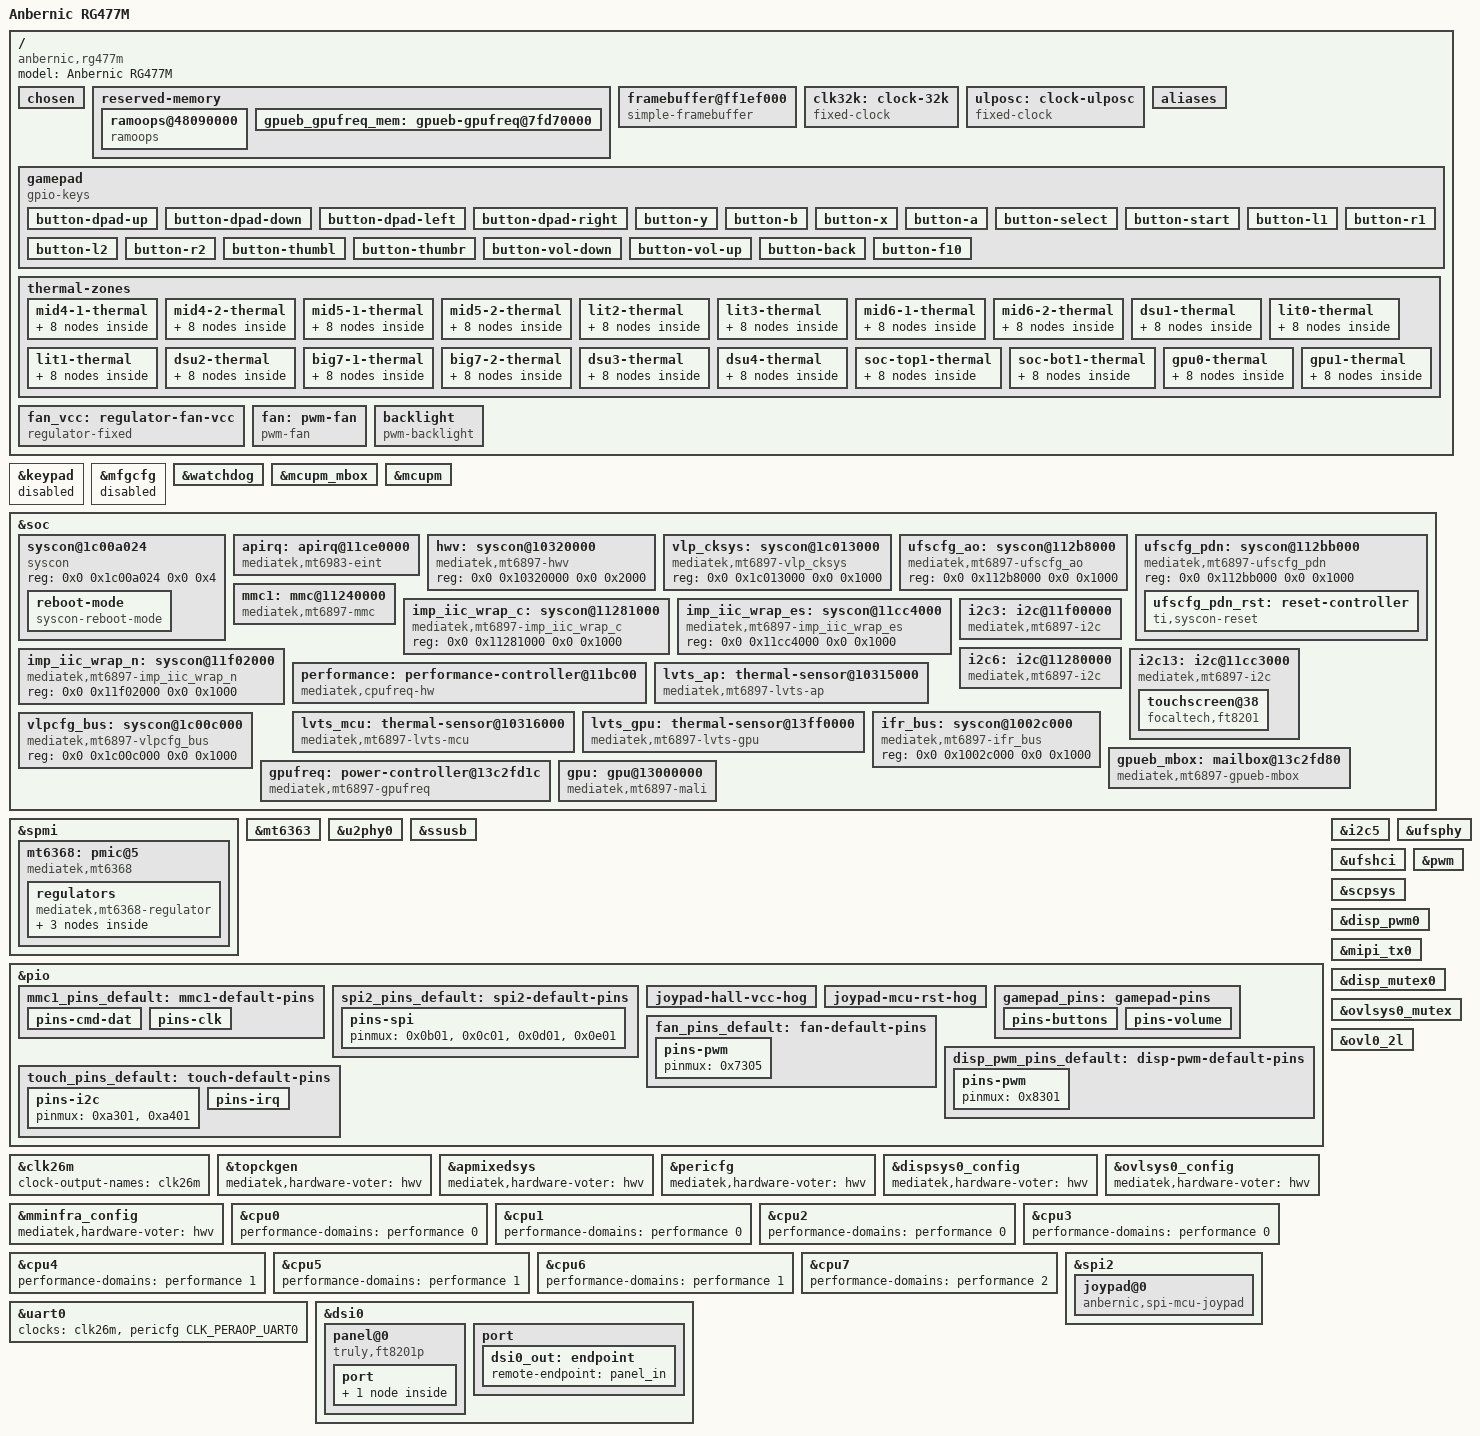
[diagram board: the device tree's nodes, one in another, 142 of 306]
// SPDX-License-Identifier: GPL-2.0 OR BSD-3-Clause
/*
 * Anbernic RG477M (MediaTek MT6897 / Dimensity 8300) - first-boot board file.
 *
 * This tree is embedded in the kernel (CONFIG_ARM64_EMBEDDED_DTB). The
 * bootloader is given the stock vendor tree; early boot code takes memory size,
 * the initramfs location and every /reserved-memory region from that tree and
 * then switches to this one. So there is deliberately no /memory node and no
 * copy of the bootloader's reserved regions here.
 *
 * Stage 1 goal: reach an initramfs with the kernel log visible on the panel
 * (bootloader framebuffer) and preserved in ramoops.
 *
 * Stage 2 adds the watchdog, the PMIC bus and USB device mode. There is no
 * clock driver yet: nodes use 26 MHz placeholders and rely on the state the
 * bootloader left behind (clk_ignore_unused).
 */

/dts-v1/;
#include "mt6897.dtsi"
#include <dt-bindings/clock/mt6897-clk.h>

/ {
	model = "Anbernic RG477M";
	compatible = "anbernic,rg477m", "mediatek,mt6897";

	/*
	 * The bootloader leaves the hardware watchdog armed (about 28 s). The
	 * driver takes it over and the core keeps it fed for
	 * watchdog.open_timeout seconds; after that userspace must hold
	 * /dev/watchdog open, so a boot that never reaches a working init is
	 * still reset and falls back to the other slot.
	 */
	chosen {
		bootargs = "bootconfig console=ttyS0,921600n8 console=tty0 ignore_loglevel printk.devkmsg=on clk_ignore_unused pd_ignore_unused panic=5 watchdog.open_timeout=45";
	};

	reserved-memory {
		#address-cells = <2>;
		#size-cells = <2>;
		ranges;

		/*
		 * Same region and zone layout as the vendor kernel (which gets it from
		 * ramoops.* parameters with 4 KiB record and ftrace zones), so the log
		 * written here is readable as /sys/fs/pstore/console-ramoops-0 after the
		 * device has fallen back to Android. The bootloader marks this region
		 * no-map; that is carried over by the early import.
		 */
		ramoops@48090000 {
			compatible = "ramoops";
			reg = <0x0 0x48090000 0x0 0xe0000>;
			record-size = <0x1000>;
			console-size = <0x40000>;
			ftrace-size = <0x1000>;
			pmsg-size = <0x80000>;
		};

		/*
		 * MEM_ID_GPUFREQ: the first 0x4000 bytes of the bootloader's
		 * me_GPUEB_SHARED (0x7fd70000 + 0x180000 on this board; the
		 * tablet's 0x7fe70000 in mt6897.dtsi is not ours). The GPUEB
		 * writes struct gpufreq_shared_status here after
		 * CMD_INIT_SHARED_MEM. The early import already marks the whole
		 * region no-map; this node only lets the driver find it.
		 */
		gpueb_gpufreq_mem: gpueb-gpufreq@7fd70000 {
			reg = <0x0 0x7fd70000 0x0 0x4000>;
			no-map;
		};
	};

	/*
	 * Scan-out buffer left running by the bootloader (its mblock "framebuffer":
	 * 0xff1ef000, 0xe10000 bytes = 3 x 1280x960x4). The region itself is taken
	 * from the bootloader tree and kept out of the linear map by the early
	 * import. The address was read on a 12 GB unit; if another RAM size places
	 * it elsewhere, read it from the bootloader tree instead of fixing it here.
	 */
	framebuffer@ff1ef000 {
		compatible = "simple-framebuffer";
		reg = <0x0 0xff1ef000 0x0 0xe10000>;
		width = <1280>;
		height = <960>;
		stride = <5120>;
		format = "a8r8g8b8";
		/*
		 * The bootloader's pipeline runs from mmpll (disp0, ovl0 and
		 * mminfra all select mmpll_d4). Hold those here: UFS borrows
		 * mmpll_d6 during bring-up, and when it lets go the PLL would
		 * otherwise be switched off under the panel (seen as the
		 * console going black at SCSI attach).
		 */
		clocks = <&topckgen CLK_TOP_DISP0_SEL>,
			 <&topckgen CLK_TOP_OVL0_SEL>,
			 <&topckgen CLK_TOP_MMINFRA_SEL>,
			 <&pericfg CLK_PERAOP_DISP_PWM0>;
	};
};

/*
 * The SoC file's gpu and gpueb nodes belong to the vendor-derived GPUEB path
 * of the tablet (CONFIG_MTK_GPUEB, wrong shared-memory address for this board,
 * mfgcfg clocks). Drop them so nothing on this board can match that driver or
 * the panthor hooks keyed on a "mediatek,gpueb" node; the GPU is described
 * again below for the mainline mailbox + mt6897-gpufreq power domain.
 */
/delete-node/ &gpu;
/delete-node/ &gpueb;

/* Nothing below is needed to reach an initramfs; enable one at a time later. */

&keypad {
	status = "disabled";
};

&mfgcfg {
	status = "disabled";
};



&watchdog {
	status = "okay";
};

/*
 * MCUPM mailbox and bring-up client (CPU idle states experiment): the client
 * sends the vendor's platform IPI and timesync at probe, each switchable with
 * mtk_mcupm_mt6897.ping= / .timesync=, and logs the ATF/MCUPM state words.
 */
&mcupm_mbox {
	status = "okay";
};

&mcupm {
	status = "okay";
};

&soc {
	/*
	 * The bootloader reads its boot mode from the low nibble of the
	 * watchdog's non-reset register 2 (0x1c00a024), same as the vendor
	 * tree's reboot-mode node. "reboot bootloader" lands in fastboot, where
	 * the host can switch the active slot back without waiting for the
	 * retry counter to run out. Kept as its own syscon so the watchdog
	 * driver can own the main register block.
	 */
	syscon@1c00a024 {
		compatible = "syscon", "simple-mfd";
		reg = <0x0 0x1c00a024 0x0 0x4>;

		reboot-mode {
			compatible = "syscon-reboot-mode";
			offset = <0x0>;
			mask = <0xf>;
			mode-charger = <0x1>;
			mode-recovery = <0x2>;
			mode-bootloader = <0x3>;
		};
	};
};

/*
 * PMIC bus. The PMIC interrupt line is EINT 248 of the pin controller (the
 * dtsi already says so). Only VUSB is described, with the vendor tree's limits
 * and always-on, so nothing changes any rail's state or voltage. The power
 * and volume-down ("home") keys on the MT6363 are polled by the keys driver.
 */
&spmi {
	status = "okay";

	mt6368: pmic@5 {
		compatible = "mediatek,mt6368";
		reg = <5 0>;
		interrupts = <5>;
		interrupt-controller;
		#interrupt-cells = <2>;

		regulators {
			compatible = "mediatek,mt6368-regulator";

			mt6368_vusb: VUSB {
				regulator-compatible = "VUSB";
				regulator-name = "mt6368_vusb";
				regulator-min-microvolt = <1200000>;
				regulator-max-microvolt = <3500000>;
				regulator-enable-ramp-delay = <680>;
				regulator-always-on;
			};

			/*
			 * SD card supplies. The stock tree lists the LDOs' full
			 * 1.2-3.5 V range and limits the card to 3.0 V with a
			 * vendor-only "ocr-voltage" property; without that the
			 * MMC core picked 3.5 V for both rails. Limit them here:
			 * 3.0 V card supply, 1.8-3.0 V signalling.
			 */
			mt6368_vmch_eint_high: VMCH_EINT_HIGH {
				regulator-compatible = "VMCH_EINT_HIGH";
				regulator-name = "mt6368_vmch_eint_high";
				regulator-min-microvolt = <2800000>;
				regulator-max-microvolt = <3000000>;
				regulator-enable-ramp-delay = <680>;
			};

			mt6368_vmc: VMC {
				regulator-compatible = "VMC";
				regulator-name = "mt6368_vmc";
				regulator-min-microvolt = <1800000>;
				regulator-max-microvolt = <3000000>;
				regulator-enable-ramp-delay = <680>;
			};
		};
	};
};

&mt6363 {
	interrupts = <4>;
	interrupt-controller;
	#interrupt-cells = <2>;
};

/* USB device mode only; no Type-C role detection yet. */
&u2phy0 {
	status = "okay";
};

&ssusb {
	dr_mode = "peripheral";
	maximum-speed = "high-speed";
	mediatek,force-vbus;
	phys = <&u2port0 PHY_TYPE_USB2>;
	vusb33-supply = <&mt6368_vusb>;
	status = "okay";
};

/*
 * Pin controller. Register block names and order, and the EINT block with its
 * number -> (instance, index, debounce) table, are the stock tree's.
 */
&soc {
	apirq: apirq@11ce0000 {
		compatible = "mediatek,mt6983-eint";
		reg = <0x0 0x11ce0000 0x0 0x1000>,
		      <0x0 0x11de0000 0x0 0x1000>,
		      <0x0 0x11e90000 0x0 0x1000>,
		      <0x0 0x11fe0000 0x0 0x1000>,
		      <0x0 0x1c01e000 0x0 0x1000>;
		reg-names = "eint-e", "eint-s", "eint-w", "eint-n", "eint-c";
		interrupts = <GIC_SPI 309 IRQ_TYPE_LEVEL_HIGH 0>;
		mediatek,instance-num = <5>;
		mediatek,total-pin-number = <250>;
		mediatek,pins = <
			0x00 0x03 0x00 0x01 0x01 0x03 0x01 0x01 0x02 0x03 0x02 0x01 0x03 0x03 0x03 0x01
			0x04 0x00 0x00 0x01 0x05 0x00 0x01 0x01 0x06 0x00 0x02 0x01 0x07 0x03 0x04 0x01
			0x08 0x02 0x00 0x01 0x09 0x03 0x05 0x01 0x0a 0x03 0x06 0x01 0x0b 0x03 0x07 0x01
			0x0c 0x03 0x08 0x01 0x0d 0x03 0x09 0x01 0x0e 0x03 0x0a 0x01 0x0f 0x01 0x00 0x01
			0x10 0x01 0x01 0x01 0x11 0x01 0x02 0x01 0x12 0x01 0x03 0x01 0x13 0x01 0x04 0x01
			0x14 0x01 0x05 0x01 0x15 0x01 0x06 0x01 0x16 0x01 0x07 0x01 0x17 0x01 0x08 0x01
			0x18 0x01 0x09 0x01 0x19 0x01 0x0a 0x01 0x1a 0x01 0x0b 0x01 0x1b 0x01 0x0c 0x01
			0x1c 0x01 0x0d 0x01 0x1d 0x01 0x0e 0x01 0x1e 0x01 0x0f 0x01 0x1f 0x02 0x01 0x01
			0x20 0x02 0x02 0x01 0x21 0x02 0x03 0x01 0x22 0x02 0x04 0x01 0x23 0x02 0x05 0x00
			0x24 0x01 0x10 0x00 0x25 0x01 0x11 0x00 0x26 0x01 0x12 0x00 0x27 0x01 0x13 0x00
			0x28 0x03 0x0b 0x00 0x29 0x03 0x0c 0x00 0x2a 0x03 0x0d 0x00 0x2b 0x03 0x0e 0x00
			0x2c 0x00 0x03 0x00 0x2d 0x00 0x04 0x00 0x2e 0x00 0x05 0x00 0x2f 0x00 0x06 0x00
			0x30 0x00 0x07 0x00 0x31 0x00 0x08 0x00 0x32 0x02 0x06 0x00 0x33 0x02 0x07 0x00
			0x34 0x02 0x08 0x00 0x35 0x02 0x09 0x00 0x36 0x03 0x0f 0x00 0x37 0x03 0x10 0x00
			0x38 0x03 0x11 0x00 0x39 0x03 0x12 0x00 0x3a 0x03 0x13 0x00 0x3b 0x03 0x14 0x00
			0x3c 0x03 0x15 0x00 0x3d 0x03 0x16 0x00 0x3e 0x00 0x09 0x00 0x3f 0x00 0x0a 0x00
			0x40 0x00 0x0b 0x00 0x41 0x00 0x0c 0x00 0x42 0x02 0x0a 0x00 0x43 0x02 0x0b 0x00
			0x44 0x02 0x0c 0x00 0x45 0x02 0x0d 0x00 0x46 0x02 0x0e 0x00 0x47 0x02 0x0f 0x00
			0x48 0x02 0x10 0x00 0x49 0x02 0x11 0x00 0x4a 0x02 0x12 0x00 0x4b 0x02 0x13 0x00
			0x4c 0x02 0x14 0x00 0x4d 0x02 0x15 0x00 0x4e 0x00 0x0d 0x00 0x4f 0x00 0x0e 0x00
			0x50 0x00 0x0f 0x00 0x51 0x00 0x10 0x00 0x52 0x00 0x11 0x00 0x53 0x00 0x12 0x00
			0x54 0x01 0x14 0x00 0x55 0x01 0x15 0x00 0x56 0x01 0x16 0x00 0x57 0x01 0x17 0x00
			0x58 0x01 0x18 0x00 0x59 0x01 0x19 0x00 0x5a 0x01 0x1a 0x00 0x5b 0x01 0x1b 0x00
			0x5c 0x01 0x1c 0x00 0x5d 0x01 0x1d 0x00 0x5e 0x01 0x1e 0x00 0x5f 0x01 0x1f 0x00
			0x60 0x01 0x20 0x00 0x61 0x01 0x21 0x00 0x62 0x01 0x22 0x00 0x63 0x01 0x23 0x00
			0x64 0x01 0x24 0x00 0x65 0x01 0x25 0x00 0x66 0x01 0x26 0x00 0x67 0x01 0x27 0x00
			0x68 0x01 0x28 0x00 0x69 0x01 0x29 0x00 0x6a 0x01 0x2a 0x00 0x6b 0x01 0x2b 0x00
			0x6c 0x01 0x2c 0x00 0x6d 0x01 0x2d 0x00 0x6e 0x01 0x2e 0x00 0x6f 0x01 0x2f 0x00
			0x70 0x01 0x30 0x00 0x71 0x01 0x31 0x00 0x72 0x01 0x32 0x00 0x73 0x00 0x13 0x00
			0x74 0x00 0x14 0x00 0x75 0x00 0x15 0x00 0x76 0x01 0x33 0x00 0x77 0x00 0x16 0x00
			0x78 0x00 0x17 0x00 0x79 0x00 0x18 0x00 0x7a 0x01 0x34 0x00 0xe8 0x04 0x00 0x00
			0xe9 0x04 0x01 0x00 0xea 0x04 0x02 0x00 0xeb 0x04 0x03 0x00 0xec 0x04 0x04 0x00
			0xed 0x04 0x05 0x00 0xee 0x04 0x06 0x00 0xef 0x04 0x07 0x00 0xf0 0x04 0x08 0x00
			0xf1 0x04 0x09 0x00 0xf2 0x04 0x0a 0x00 0xf3 0x04 0x0b 0x00 0xf4 0x04 0x0c 0x00
			0xf5 0x04 0x0d 0x00 0xf6 0x04 0x0e 0x00 0xf7 0x04 0x0f 0x00 0xf8 0x04 0x10 0x00
			0xf9 0x04 0x11 0x00>;
	};
};

&pio {
	reg-names = "gpio", "iocfg_rt", "iocfg_rm", "iocfg_bl", "iocfg_bm",
		    "iocfg_br", "iocfg_lb", "iocfg_lt", "iocfg_tm", "iocfg_tl";
	gpio-ranges = <&pio 0 0 250>;
	mediatek,eint = <&apirq>;
};

/*
 * Clock controllers. Registration only for now: no consumer references them
 * yet and the kernel runs with clk_ignore_unused, so the tree mirrors the state
 * the bootloader left. The CPU, GPU and SCP PLL blocks are left out until
 * something needs them. Do not add assigned-clocks to these nodes.
 */
&clk26m {
	clock-output-names = "clk26m";
};

/ {
	clk32k: clock-32k {
		compatible = "fixed-clock";
		#clock-cells = <0>;
		clock-frequency = <32000>;
		clock-output-names = "clk32k";
	};

	ulposc: clock-ulposc {
		compatible = "fixed-clock";
		#clock-cells = <0>;
		clock-frequency = <588000000>;
		clock-output-names = "ulposc";
	};
};

&soc {
	hwv: syscon@10320000 {
		compatible = "mediatek,mt6897-hwv", "syscon";
		reg = <0x0 0x10320000 0x0 0x2000>;
	};

	vlp_cksys: syscon@1c013000 {
		compatible = "mediatek,mt6897-vlp_cksys", "syscon";
		reg = <0x0 0x1c013000 0x0 0x1000>;
		#clock-cells = <1>;
	};

	ufscfg_ao: syscon@112b8000 {
		compatible = "mediatek,mt6897-ufscfg_ao", "syscon";
		reg = <0x0 0x112b8000 0x0 0x1000>;
		#clock-cells = <1>;
	};

	ufscfg_pdn: syscon@112bb000 {
		compatible = "mediatek,mt6897-ufscfg_pdn", "syscon", "simple-mfd";
		reg = <0x0 0x112bb000 0x0 0x1000>;
		#clock-cells = <1>;

		/* UniPro, crypto and host controller resets, as in the stock tree. */
		ufscfg_pdn_rst: reset-controller {
			compatible = "ti,syscon-reset";
			#reset-cells = <1>;
			ti,reset-bits = <0x48 0 0x4c 0 0 0 0x1c>,
					<0x48 1 0x4c 1 0 0 0x1c>,
					<0x48 2 0x4c 2 0 0 0x1c>;
		};
	};
};

&topckgen {
	mediatek,hardware-voter = <&hwv>;
};

&apmixedsys {
	mediatek,hardware-voter = <&hwv>;
};

&pericfg {
	mediatek,hardware-voter = <&hwv>;
};

/*
 * Display clock gates used by the bootloader's pipeline (DSI0 path through
 * dispsys0/ovlsys0, SMI/GCE on mminfra). Registration is read-free and
 * write-free; the gates are only touched once a consumer enables them.
 * The three power domains are registered on and always-on by scpsys.
 */
&dispsys0_config {
	mediatek,hardware-voter = <&hwv>;
	status = "okay";
};

&ovlsys0_config {
	mediatek,hardware-voter = <&hwv>;
	status = "okay";
};

&mminfra_config {
	mediatek,hardware-voter = <&hwv>;
	status = "okay";
};

/*
 * microSD slot (MSDC1). Pins, supplies and card detect are the stock tree's;
 * its raw drive-strength index 3 is 8 mA.
 */
&pio {
	mmc1_pins_default: mmc1-default-pins {
		pins-cmd-dat {
			pinmux = <0x4a01>, <0x4b01>, <0x4c01>, <0x4d01>, <0x4901>;
			input-enable;
			drive-strength = <8>;
			bias-pull-up = <101>;
		};

		pins-clk {
			pinmux = <0x4801>;
			drive-strength = <8>;
			bias-pull-down = <102>;
		};
	};
};

&soc {
	mmc1: mmc@11240000 {
		compatible = "mediatek,mt6897-mmc";
		reg = <0x0 0x11240000 0x0 0x1000>,
		      <0x0 0x11e00000 0x0 0x1000>;
		interrupts = <GIC_SPI 166 IRQ_TYPE_LEVEL_HIGH 0>;
		clocks = <&topckgen CLK_TOP_MSDC30_1_SEL>,
			 <&pericfg CLK_PERAOP_MSDC1_HCLK>,
			 <&pericfg CLK_PERAOP_MSDC1>,
			 <&pericfg CLK_PERAOP_MSDC1_FCLK>;
		/*
		 * PERAOP_MSDC1 is deliberately not "source_cg": the driver
		 * gates that clock while it programs the divider, and on this
		 * SoC the same gate also clocks the register interface, so the
		 * divider write was lost (CKDIV read back 0 and the card was
		 * clocked far too fast). The vendor driver never gates it here
		 * (need_gate_cg = false).
		 */
		clock-names = "source", "hclk", "pclk_cg", "axi_cg";
		pinctrl-names = "default", "state_uhs";
		pinctrl-0 = <&mmc1_pins_default>;
		pinctrl-1 = <&mmc1_pins_default>;
		bus-width = <4>;
		max-frequency = <200000000>;
		cap-sd-highspeed;
		sd-uhs-sdr12;
		sd-uhs-sdr25;
		sd-uhs-sdr50;
		sd-uhs-sdr104;
		cd-gpios = <&pio 33 GPIO_ACTIVE_LOW>;
		vmmc-supply = <&mt6368_vmch_eint_high>;
		vqmmc-supply = <&mt6368_vmc>;
		no-mmc;
		no-sdio;
		status = "okay";
	};
};

/*
 * I2C. Only the buses with board devices on them: i2c3 (RT9465 charger),
 * i2c5 (MT6375 charger/Type-C, RT6160, RT5133), i2c6 (panel gate IC, PS5170
 * redriver, speaker amp, flash LED driver), i2c13 (touchscreen). No client
 * devices are described yet; the buses are up for probing only. Pins are left
 * as the bootloader muxed them, as in the stock tree.
 */
&soc {
	imp_iic_wrap_c: syscon@11281000 {
		compatible = "mediatek,mt6897-imp_iic_wrap_c", "syscon";
		reg = <0x0 0x11281000 0x0 0x1000>;
		#clock-cells = <1>;
	};

	imp_iic_wrap_es: syscon@11cc4000 {
		compatible = "mediatek,mt6897-imp_iic_wrap_es", "syscon";
		reg = <0x0 0x11cc4000 0x0 0x1000>;
		#clock-cells = <1>;
	};

	imp_iic_wrap_n: syscon@11f02000 {
		compatible = "mediatek,mt6897-imp_iic_wrap_n", "syscon";
		reg = <0x0 0x11f02000 0x0 0x1000>;
		#clock-cells = <1>;
	};

	i2c3: i2c@11f00000 {
		compatible = "mediatek,mt6897-i2c";
		reg = <0x0 0x11f00000 0x0 0x1000>,
		      <0x0 0x11300400 0x0 0x80>;
		interrupts = <GIC_SPI 189 IRQ_TYPE_LEVEL_HIGH 0>;
		clocks = <&imp_iic_wrap_n CLK_IMPN_AP_CLOCK_I2C3>,
			 <&pericfg CLK_PERAOP_DMA_BCLK>;
		clock-names = "main", "dma";
		clock-div = <1>;
		clock-frequency = <100000>;
		#address-cells = <1>;
		#size-cells = <0>;
	};

	i2c6: i2c@11280000 {
		compatible = "mediatek,mt6897-i2c";
		reg = <0x0 0x11280000 0x0 0x1000>,
		      <0x0 0x11300600 0x0 0x80>;
		interrupts = <GIC_SPI 192 IRQ_TYPE_LEVEL_HIGH 0>;
		clocks = <&imp_iic_wrap_c CLK_IMPC_AP_CLOCK>,
			 <&pericfg CLK_PERAOP_DMA_BCLK>;
		clock-names = "main", "dma";
		clock-div = <1>;
		clock-frequency = <100000>;
		#address-cells = <1>;
		#size-cells = <0>;
	};

	i2c13: i2c@11cc3000 {
		compatible = "mediatek,mt6897-i2c";
		reg = <0x0 0x11cc3000 0x0 0x1000>,
		      <0x0 0x11300b00 0x0 0x80>;
		interrupts = <GIC_SPI 199 IRQ_TYPE_LEVEL_HIGH 0>;
		clocks = <&imp_iic_wrap_es CLK_IMPES_AP_CLOCK_I2C13>,
			 <&pericfg CLK_PERAOP_DMA_BCLK>;
		clock-names = "main", "dma";
		clock-div = <1>;
		clock-frequency = <100000>;
		#address-cells = <1>;
		#size-cells = <0>;
	};
};

&i2c5 {
	clocks = <&imp_iic_wrap_n CLK_IMPN_AP_CLOCK_I2C5>,
		 <&pericfg CLK_PERAOP_DMA_BCLK>;
	clock-frequency = <100000>;
	status = "okay";
};

/ {
	aliases {
		i2c3 = &i2c3;
		i2c5 = &i2c5;
		i2c6 = &i2c6;
		i2c13 = &i2c13;
		mmc1 = &mmc1;
	};
};

/* USB on its real clocks instead of whatever the bootloader left running. */
&ssusb {
	clocks = <&topckgen CLK_TOP_USB_TOP>,
		 <&topckgen CLK_TOP_USB_XHCI>,
		 <&pericfg CLK_PERAOP_SSUSB0_FRMCNT>;
	clock-names = "sys_ck", "xhci_ck", "frmcnt_ck";
};

/*
 * CPU frequency scaling through the MCU power manager's shared tables (same
 * node as the stock tree). There is no thermal driver or fan control yet, so
 * userspace should cap scaling_max_freq until there is.
 */
&soc {
	performance: performance-controller@11bc00 {
		compatible = "mediatek,cpufreq-hw";
		reg = <0x0 0x0011bc10 0x0 0x120>,
		      <0x0 0x0011bd30 0x0 0x120>,
		      <0x0 0x0011be50 0x0 0x120>;
		reg-names = "performance-domain0", "performance-domain1",
			    "performance-domain2";
		#performance-domain-cells = <1>;
	};
};

&cpu0 { performance-domains = <&performance 0>; };
&cpu1 { performance-domains = <&performance 0>; };
&cpu2 { performance-domains = <&performance 0>; };
&cpu3 { performance-domains = <&performance 0>; };
&cpu4 { performance-domains = <&performance 1>; };
&cpu5 { performance-domains = <&performance 1>; };
&cpu6 { performance-domains = <&performance 1>; };
&cpu7 { performance-domains = <&performance 2>; };

/*
 * Analog sticks: an MCU on SPI2 (GPIO11-14), same protocol as other recent
 * Anbernic handhelds. The stock tree drives five GPIOs high for it: MCU supply
 * (27), MCU reset (28, high = running), hall sensor supply (36), and the stick
 * LED supply and enable (65, 30). The LED pair is left alone for now. Axis
 * limits are the ROCKNIX defaults for this MCU, not yet calibrated here.
 */
&pio {
	spi2_pins_default: spi2-default-pins {
		pins-spi {
			pinmux = <0x0b01>, <0x0c01>, <0x0d01>, <0x0e01>;
		};
	};

	joypad-hall-vcc-hog {
		gpio-hog;
		gpios = <36 GPIO_ACTIVE_HIGH>;
		output-high;
		line-name = "joypad-hall-vcc";
	};

	joypad-mcu-rst-hog {
		gpio-hog;
		gpios = <28 GPIO_ACTIVE_HIGH>;
		output-high;
		line-name = "joypad-mcu-rst";
	};
};

&spi2 {
	clocks = <&topckgen CLK_TOP_MAINPLL_D6_D2>,
		 <&topckgen CLK_TOP_SPI2_SEL>,
		 <&pericfg CLK_PERAOP_SPI2_BCLK>;
	clock-names = "parent-clk", "sel-clk", "spi-clk";
	pinctrl-names = "default";
	pinctrl-0 = <&spi2_pins_default>;
	status = "okay";

	joypad@0 {
		compatible = "anbernic,spi-mcu-joypad";
		reg = <0>;
		spi-max-frequency = <1400000>;
		/* Give the MCU time between chip select and the first clock. */
		spi-cs-setup-delay-ns = <100000>;
		enable-gpios = <&pio 27 GPIO_ACTIVE_HIGH>;
		poll-interval-ms = <5>;
		swap-sticks;
		abs-x-min = <2500>;
		abs-x-max = <25000>;
		abs-y-min = <2500>;
		abs-y-max = <25000>;
		abs-rx-min = <2500>;
		abs-rx-max = <25000>;
		abs-ry-min = <2500>;
		abs-ry-max = <25000>;
		deadzone-left = <3000>;
		deadzone-right = <3000>;
		deadzone-triggers = <32000>;
	};
};

/*
 * Buttons: twenty active-low GPIO switches, the list and key codes of the
 * stock tree's "singleadc-joypad" node (which has no analog inputs on this
 * board). L2/R2 are plain switches, not analog triggers.
 */
#include <dt-bindings/input/input.h>

&pio {
	gamepad_pins: gamepad-pins {
		pins-buttons {
			pinmux = <0x0100>, <0x0300>, <0x0600>, <0x0800>, <0x0a00>,
				 <0x0f00>, <0x1000>, <0x1100>, <0x1200>, <0x1300>,
				 <0x1400>, <0x1500>, <0x1600>, <0x1700>, <0x1800>,
				 <0x1900>, <0x1a00>, <0x3d00>;
			input-enable;
			bias-pull-up;
		};

		/* GPIO31/32 have R1R0 pull resistors; 101 is the stock setting. */
		pins-volume {
			pinmux = <0x1f00>, <0x2000>;
			input-enable;
			bias-pull-up = <101>;
		};
	};
};

/ {
	gamepad {
		compatible = "gpio-keys";
		label = "RG477M Gamepad";
		pinctrl-names = "default";
		pinctrl-0 = <&gamepad_pins>;

		button-dpad-up {
			label = "DPAD-UP";
			gpios = <&pio 19 GPIO_ACTIVE_LOW>;
			linux,input-type = <EV_ABS>;
			linux,code = <ABS_HAT0Y>;
			linux,input-value = <(-1)>;
			debounce-interval = <2>;
		};

		button-dpad-down {
			label = "DPAD-DOWN";
			gpios = <&pio 22 GPIO_ACTIVE_LOW>;
			linux,input-type = <EV_ABS>;
			linux,code = <ABS_HAT0Y>;
			linux,input-value = <1>;
			debounce-interval = <2>;
		};

		button-dpad-left {
			label = "DPAD-LEFT";
			gpios = <&pio 20 GPIO_ACTIVE_LOW>;
			linux,input-type = <EV_ABS>;
			linux,code = <ABS_HAT0X>;
			linux,input-value = <(-1)>;
			debounce-interval = <2>;
		};

		button-dpad-right {
			label = "DPAD-RIGHT";
			gpios = <&pio 21 GPIO_ACTIVE_LOW>;
			linux,input-type = <EV_ABS>;
			linux,code = <ABS_HAT0X>;
			linux,input-value = <1>;
			debounce-interval = <2>;
		};

		button-y { label = "BTN-Y"; gpios = <&pio 24 GPIO_ACTIVE_LOW>; linux,code = <0x134>; debounce-interval = <2>; };
		button-b { label = "BTN-B"; gpios = <&pio 26 GPIO_ACTIVE_LOW>; linux,code = <0x131>; debounce-interval = <2>; };
		button-x { label = "BTN-X"; gpios = <&pio 23 GPIO_ACTIVE_LOW>; linux,code = <0x133>; debounce-interval = <2>; };
		button-a { label = "BTN-A"; gpios = <&pio 25 GPIO_ACTIVE_LOW>; linux,code = <0x130>; debounce-interval = <2>; };
		button-select { label = "SELECT"; gpios = <&pio 8 GPIO_ACTIVE_LOW>; linux,code = <BTN_SELECT>; debounce-interval = <2>; };
		button-start { label = "START"; gpios = <&pio 10 GPIO_ACTIVE_LOW>; linux,code = <BTN_START>; debounce-interval = <2>; };
		button-l1 { label = "L1"; gpios = <&pio 16 GPIO_ACTIVE_LOW>; linux,code = <BTN_TL>; debounce-interval = <2>; };
		button-r1 { label = "R1"; gpios = <&pio 15 GPIO_ACTIVE_LOW>; linux,code = <BTN_TR>; debounce-interval = <2>; };
		button-l2 { label = "L2"; gpios = <&pio 61 GPIO_ACTIVE_LOW>; linux,code = <BTN_TL2>; debounce-interval = <5>; };
		button-r2 { label = "R2"; gpios = <&pio 1 GPIO_ACTIVE_LOW>; linux,code = <BTN_TR2>; debounce-interval = <5>; };
		button-thumbl { label = "L3"; gpios = <&pio 18 GPIO_ACTIVE_LOW>; linux,code = <BTN_THUMBL>; debounce-interval = <2>; };
		button-thumbr { label = "R3"; gpios = <&pio 6 GPIO_ACTIVE_LOW>; linux,code = <BTN_THUMBR>; debounce-interval = <2>; };
		button-vol-down { label = "VOL-DOWN"; gpios = <&pio 31 GPIO_ACTIVE_LOW>; linux,code = <KEY_VOLUMEDOWN>; debounce-interval = <2>; };
		button-vol-up { label = "VOL-UP"; gpios = <&pio 32 GPIO_ACTIVE_LOW>; linux,code = <KEY_VOLUMEUP>; debounce-interval = <2>; };
		button-back { label = "BACK"; gpios = <&pio 17 GPIO_ACTIVE_LOW>; linux,code = <KEY_BACK>; debounce-interval = <2>; };
		button-f10 { label = "F10"; gpios = <&pio 3 GPIO_ACTIVE_LOW>; linux,code = <KEY_F10>; debounce-interval = <2>; };
	};
};

/*
 * UFS: clocks and host resets as in the stock tree. No supplies yet, so the
 * kernel cannot power-cycle the device and the rails stay as the bootloader
 * left them; that waits for suspend/power-off work, where a wrong voltage
 * limit would matter. Single interrupt, MCQ off.
 * This holds the Android installation: test userspace marks every disk
 * read-only as it appears and nothing here may mount it read-write.
 */
&ufsphy {
	status = "okay";
};

&ufshci {
	clocks = <&topckgen CLK_TOP_U_SEL>,
		 <&topckgen CLK_TOP_MAINPLL_D4_D2>,
		 <&topckgen CLK_TOP_MMPLL_D6>,
		 <&topckgen CLK_TOP_AES_UFSFDE_SEL>,
		 <&topckgen CLK_TOP_UNIVPLL_D6>,
		 <&topckgen CLK_TOP_MAINPLL_D4>,
		 <&ufscfg_ao CLK_UFSCFG_AO_UNIPRO_TX_SYMBOLCLK>,
		 <&ufscfg_ao CLK_UFSCFG_AO_UNIPRO_RX_SYMBOLCLK0>,
		 <&ufscfg_ao CLK_UFSCFG_AO_UNIPRO_RX_SYMBOLCLK1>,
		 <&ufscfg_ao CLK_UFSCFG_AO_UNIPRO_SYSCLK>,
		 <&ufscfg_pdn CLK_UFSCFG_UFSHCI_UFS>,
		 <&ufscfg_pdn CLK_UFSCFG_UFSHCI_AES>;
	clock-names = "ufs_sel", "ufs_sel_min_src", "ufs_sel_max_src",
		      "ufs_fde", "ufs_fde_min_src", "ufs_fde_max_src",
		      "unipro_tx_sym", "unipro_rx_sym0", "unipro_rx_sym1",
		      "unipro_sysclk", "ufshci_ufs", "ufshci_aes";
	freq-table-hz = <273000000 458333313>, <0 0>, <0 0>, <0 0>, <0 0>,
			<0 0>, <0 0>, <0 0>, <0 0>, <0 0>, <0 0>, <0 0>;
	mediatek,ufs-pmc-via-fastauto;
	mediatek,ufs-tx-skew-fix;
	mediatek,ufs-disable-mcq;
	resets = <&ufscfg_pdn_rst 0>, <&ufscfg_pdn_rst 1>, <&ufscfg_pdn_rst 2>;
	reset-names = "unipro_rst", "crypto_rst", "hci_rst";
	status = "okay";
};

/*
 * UART0, clocks as in the stock tree. The board has what looks like a UART
 * header, but nothing is connected to it yet, so this is only known to probe.
 * Pins are left as the bootloader muxed them. It is also a kernel console
 * (921600 8N1), listed before tty0 so the panel stays the primary console.
 */
&uart0 {
	clocks = <&clk26m>, <&pericfg CLK_PERAOP_UART0>;
	clock-names = "baud", "bus";
	status = "okay";
};

/ {
	aliases {
		serial0 = &uart0;
	};
};

/*
 * Thermal sensors (LVTS). The bootloader programs the controllers, including
 * the 119 C hardware reset; the driver only reads them, so the zones are
 * polled. The CPU, SoC and GPU domains are described; the APU block sits in a
 * power domain nothing here powers. The GPU controller (0x13ff0000) is inside
 * the GPU power domain: its node is a consumer of that domain but never keeps
 * it on, is only read while the domain is on, and reports -EAGAIN (no
 * reading) while the GPU is off. Calibration falls back to defaults
 * (about 0.4 C off on this unit) until there is an nvmem provider for the
 * bootloader's devinfo copy. CPUs throttle from 95 C; the stock tree's only
 * trip is at the hardware limit.
 */
#include <dt-bindings/thermal/mediatek,lvts-thermal.h>
#include <dt-bindings/thermal/thermal.h>

&soc {
	lvts_ap: thermal-sensor@10315000 {
		compatible = "mediatek,mt6897-lvts-ap";
		reg = <0x0 0x10315000 0x0 0x1000>;
		interrupts = <GIC_SPI 264 IRQ_TYPE_LEVEL_HIGH 0>;
		#thermal-sensor-cells = <1>;
	};

	lvts_mcu: thermal-sensor@10316000 {
		compatible = "mediatek,mt6897-lvts-mcu";
		reg = <0x0 0x10316000 0x0 0x1000>;
		interrupts = <GIC_SPI 265 IRQ_TYPE_LEVEL_HIGH 0>;
		#thermal-sensor-cells = <1>;
	};

	/* vendor lvts node: 4th reg range and 4th interrupt (SPI 0x250) */
	lvts_gpu: thermal-sensor@13ff0000 {
		compatible = "mediatek,mt6897-lvts-gpu";
		reg = <0x0 0x13ff0000 0x0 0x1000>;
		interrupts = <GIC_SPI 592 IRQ_TYPE_LEVEL_HIGH 0>;
		power-domains = <&gpufreq>;
		#thermal-sensor-cells = <1>;
	};
};

&cpu0 { #cooling-cells = <2>; };
&cpu1 { #cooling-cells = <2>; };
&cpu2 { #cooling-cells = <2>; };
&cpu3 { #cooling-cells = <2>; };
&cpu4 { #cooling-cells = <2>; };
&cpu5 { #cooling-cells = <2>; };
&cpu6 { #cooling-cells = <2>; };
&cpu7 { #cooling-cells = <2>; };

/ {
	thermal-zones {
		mid4-1-thermal {
			polling-delay = <1000>;
			polling-delay-passive = <250>;
			thermal-sensors = <&lvts_mcu MT6897_MCU_MEDIUM_CPU4_0>;

			trips {
				medium_core4_1_passive: trip-passive {
					temperature = <95000>;
					hysteresis = <2000>;
					type = "passive";
				};
				medium_core4_1_fan_low: trip-fan-low {
					temperature = <70000>;
					hysteresis = <5000>;
					type = "active";
				};
				medium_core4_1_fan_high: trip-fan-high {
					temperature = <85000>;
					hysteresis = <5000>;
					type = "active";
				};
			};

			cooling-maps {
				map0 {
					trip = <&medium_core4_1_passive>;
					cooling-device = <&cpu0 THERMAL_NO_LIMIT THERMAL_NO_LIMIT>,
							 <&cpu4 THERMAL_NO_LIMIT THERMAL_NO_LIMIT>,
							 <&cpu7 THERMAL_NO_LIMIT THERMAL_NO_LIMIT>;
				};
				map1 {
					trip = <&medium_core4_1_fan_low>;
					cooling-device = <&fan 1 1>;
				};
				map2 {
					trip = <&medium_core4_1_fan_high>;
					cooling-device = <&fan 2 2>;
				};
			};
		};

		mid4-2-thermal {
			polling-delay = <1000>;
			polling-delay-passive = <250>;
			thermal-sensors = <&lvts_mcu MT6897_MCU_MEDIUM_CPU4_1>;

			trips {
				medium_core4_2_passive: trip-passive {
					temperature = <95000>;
					hysteresis = <2000>;
					type = "passive";
				};
				medium_core4_2_fan_low: trip-fan-low {
					temperature = <70000>;
					hysteresis = <5000>;
					type = "active";
				};
				medium_core4_2_fan_high: trip-fan-high {
					temperature = <85000>;
					hysteresis = <5000>;
					type = "active";
				};
			};

			cooling-maps {
				map0 {
					trip = <&medium_core4_2_passive>;
					cooling-device = <&cpu0 THERMAL_NO_LIMIT THERMAL_NO_LIMIT>,
							 <&cpu4 THERMAL_NO_LIMIT THERMAL_NO_LIMIT>,
							 <&cpu7 THERMAL_NO_LIMIT THERMAL_NO_LIMIT>;
				};
				map1 {
					trip = <&medium_core4_2_fan_low>;
					cooling-device = <&fan 1 1>;
				};
				map2 {
					trip = <&medium_core4_2_fan_high>;
					cooling-device = <&fan 2 2>;
				};
			};
		};

		mid5-1-thermal {
			polling-delay = <1000>;
			polling-delay-passive = <250>;
			thermal-sensors = <&lvts_mcu MT6897_MCU_MEDIUM_CPU5_0>;

			trips {
				medium_core5_1_passive: trip-passive {
					temperature = <95000>;
					hysteresis = <2000>;
					type = "passive";
				};
				medium_core5_1_fan_low: trip-fan-low {
					temperature = <70000>;
					hysteresis = <5000>;
					type = "active";
				};
				medium_core5_1_fan_high: trip-fan-high {
					temperature = <85000>;
					hysteresis = <5000>;
					type = "active";
				};
			};

			cooling-maps {
				map0 {
					trip = <&medium_core5_1_passive>;
					cooling-device = <&cpu0 THERMAL_NO_LIMIT THERMAL_NO_LIMIT>,
							 <&cpu4 THERMAL_NO_LIMIT THERMAL_NO_LIMIT>,
							 <&cpu7 THERMAL_NO_LIMIT THERMAL_NO_LIMIT>;
				};
				map1 {
					trip = <&medium_core5_1_fan_low>;
					cooling-device = <&fan 1 1>;
				};
				map2 {
					trip = <&medium_core5_1_fan_high>;
					cooling-device = <&fan 2 2>;
				};
			};
		};

		mid5-2-thermal {
			polling-delay = <1000>;
			polling-delay-passive = <250>;
			thermal-sensors = <&lvts_mcu MT6897_MCU_MEDIUM_CPU5_1>;

			trips {
				medium_core5_2_passive: trip-passive {
					temperature = <95000>;
					hysteresis = <2000>;
					type = "passive";
				};
				medium_core5_2_fan_low: trip-fan-low {
					temperature = <70000>;
					hysteresis = <5000>;
					type = "active";
				};
				medium_core5_2_fan_high: trip-fan-high {
					temperature = <85000>;
					hysteresis = <5000>;
					type = "active";
				};
			};

			cooling-maps {
				map0 {
					trip = <&medium_core5_2_passive>;
					cooling-device = <&cpu0 THERMAL_NO_LIMIT THERMAL_NO_LIMIT>,
							 <&cpu4 THERMAL_NO_LIMIT THERMAL_NO_LIMIT>,
							 <&cpu7 THERMAL_NO_LIMIT THERMAL_NO_LIMIT>;
				};
				map1 {
					trip = <&medium_core5_2_fan_low>;
					cooling-device = <&fan 1 1>;
				};
				map2 {
					trip = <&medium_core5_2_fan_high>;
					cooling-device = <&fan 2 2>;
				};
			};
		};

		lit2-thermal {
			polling-delay = <1000>;
			polling-delay-passive = <250>;
			thermal-sensors = <&lvts_mcu MT6897_MCU_LITTLE_CPU2>;

			trips {
				little_core2_passive: trip-passive {
					temperature = <95000>;
					hysteresis = <2000>;
					type = "passive";
				};
				little_core2_fan_low: trip-fan-low {
					temperature = <70000>;
					hysteresis = <5000>;
					type = "active";
				};
				little_core2_fan_high: trip-fan-high {
					temperature = <85000>;
					hysteresis = <5000>;
					type = "active";
				};
			};

			cooling-maps {
				map0 {
					trip = <&little_core2_passive>;
					cooling-device = <&cpu0 THERMAL_NO_LIMIT THERMAL_NO_LIMIT>,
							 <&cpu4 THERMAL_NO_LIMIT THERMAL_NO_LIMIT>,
							 <&cpu7 THERMAL_NO_LIMIT THERMAL_NO_LIMIT>;
				};
				map1 {
					trip = <&little_core2_fan_low>;
					cooling-device = <&fan 1 1>;
				};
				map2 {
					trip = <&little_core2_fan_high>;
					cooling-device = <&fan 2 2>;
				};
			};
		};

		lit3-thermal {
			polling-delay = <1000>;
			polling-delay-passive = <250>;
			thermal-sensors = <&lvts_mcu MT6897_MCU_LITTLE_CPU3>;

			trips {
				little_core3_passive: trip-passive {
					temperature = <95000>;
					hysteresis = <2000>;
					type = "passive";
				};
				little_core3_fan_low: trip-fan-low {
					temperature = <70000>;
					hysteresis = <5000>;
					type = "active";
				};
				little_core3_fan_high: trip-fan-high {
					temperature = <85000>;
					hysteresis = <5000>;
					type = "active";
				};
			};

			cooling-maps {
				map0 {
					trip = <&little_core3_passive>;
					cooling-device = <&cpu0 THERMAL_NO_LIMIT THERMAL_NO_LIMIT>,
							 <&cpu4 THERMAL_NO_LIMIT THERMAL_NO_LIMIT>,
							 <&cpu7 THERMAL_NO_LIMIT THERMAL_NO_LIMIT>;
				};
				map1 {
					trip = <&little_core3_fan_low>;
					cooling-device = <&fan 1 1>;
				};
				map2 {
					trip = <&little_core3_fan_high>;
					cooling-device = <&fan 2 2>;
				};
			};
		};

		mid6-1-thermal {
			polling-delay = <1000>;
			polling-delay-passive = <250>;
			thermal-sensors = <&lvts_mcu MT6897_MCU_MEDIUM_CPU6_0>;

			trips {
				medium_core6_1_passive: trip-passive {
					temperature = <95000>;
					hysteresis = <2000>;
					type = "passive";
				};
				medium_core6_1_fan_low: trip-fan-low {
					temperature = <70000>;
					hysteresis = <5000>;
					type = "active";
				};
				medium_core6_1_fan_high: trip-fan-high {
					temperature = <85000>;
					hysteresis = <5000>;
					type = "active";
				};
			};

			cooling-maps {
				map0 {
					trip = <&medium_core6_1_passive>;
					cooling-device = <&cpu0 THERMAL_NO_LIMIT THERMAL_NO_LIMIT>,
							 <&cpu4 THERMAL_NO_LIMIT THERMAL_NO_LIMIT>,
							 <&cpu7 THERMAL_NO_LIMIT THERMAL_NO_LIMIT>;
				};
				map1 {
					trip = <&medium_core6_1_fan_low>;
					cooling-device = <&fan 1 1>;
				};
				map2 {
					trip = <&medium_core6_1_fan_high>;
					cooling-device = <&fan 2 2>;
				};
			};
		};

		mid6-2-thermal {
			polling-delay = <1000>;
			polling-delay-passive = <250>;
			thermal-sensors = <&lvts_mcu MT6897_MCU_MEDIUM_CPU6_1>;

			trips {
				medium_core6_2_passive: trip-passive {
					temperature = <95000>;
					hysteresis = <2000>;
					type = "passive";
				};
				medium_core6_2_fan_low: trip-fan-low {
					temperature = <70000>;
					hysteresis = <5000>;
					type = "active";
				};
				medium_core6_2_fan_high: trip-fan-high {
					temperature = <85000>;
					hysteresis = <5000>;
					type = "active";
				};
			};

			cooling-maps {
				map0 {
					trip = <&medium_core6_2_passive>;
					cooling-device = <&cpu0 THERMAL_NO_LIMIT THERMAL_NO_LIMIT>,
							 <&cpu4 THERMAL_NO_LIMIT THERMAL_NO_LIMIT>,
							 <&cpu7 THERMAL_NO_LIMIT THERMAL_NO_LIMIT>;
				};
				map1 {
					trip = <&medium_core6_2_fan_low>;
					cooling-device = <&fan 1 1>;
				};
				map2 {
					trip = <&medium_core6_2_fan_high>;
					cooling-device = <&fan 2 2>;
				};
			};
		};

		dsu1-thermal {
			polling-delay = <1000>;
			polling-delay-passive = <250>;
			thermal-sensors = <&lvts_mcu MT6897_MCU_DSU0>;

			trips {
				dsu1_passive: trip-passive {
					temperature = <95000>;
					hysteresis = <2000>;
					type = "passive";
				};
				dsu1_fan_low: trip-fan-low {
					temperature = <70000>;
					hysteresis = <5000>;
					type = "active";
				};
				dsu1_fan_high: trip-fan-high {
					temperature = <85000>;
					hysteresis = <5000>;
					type = "active";
				};
			};

			cooling-maps {
				map0 {
					trip = <&dsu1_passive>;
					cooling-device = <&cpu0 THERMAL_NO_LIMIT THERMAL_NO_LIMIT>,
							 <&cpu4 THERMAL_NO_LIMIT THERMAL_NO_LIMIT>,
							 <&cpu7 THERMAL_NO_LIMIT THERMAL_NO_LIMIT>;
				};
				map1 {
					trip = <&dsu1_fan_low>;
					cooling-device = <&fan 1 1>;
				};
				map2 {
					trip = <&dsu1_fan_high>;
					cooling-device = <&fan 2 2>;
				};
			};
		};

		lit0-thermal {
			polling-delay = <1000>;
			polling-delay-passive = <250>;
			thermal-sensors = <&lvts_mcu MT6897_MCU_LITTLE_CPU0>;

			trips {
				little_core0_passive: trip-passive {
					temperature = <95000>;
					hysteresis = <2000>;
					type = "passive";
				};
				little_core0_fan_low: trip-fan-low {
					temperature = <70000>;
					hysteresis = <5000>;
					type = "active";
				};
				little_core0_fan_high: trip-fan-high {
					temperature = <85000>;
					hysteresis = <5000>;
					type = "active";
				};
			};

			cooling-maps {
				map0 {
					trip = <&little_core0_passive>;
					cooling-device = <&cpu0 THERMAL_NO_LIMIT THERMAL_NO_LIMIT>,
							 <&cpu4 THERMAL_NO_LIMIT THERMAL_NO_LIMIT>,
							 <&cpu7 THERMAL_NO_LIMIT THERMAL_NO_LIMIT>;
				};
				map1 {
					trip = <&little_core0_fan_low>;
					cooling-device = <&fan 1 1>;
				};
				map2 {
					trip = <&little_core0_fan_high>;
					cooling-device = <&fan 2 2>;
				};
			};
		};

		lit1-thermal {
			polling-delay = <1000>;
			polling-delay-passive = <250>;
			thermal-sensors = <&lvts_mcu MT6897_MCU_LITTLE_CPU1>;

			trips {
				little_core1_passive: trip-passive {
					temperature = <95000>;
					hysteresis = <2000>;
					type = "passive";
				};
				little_core1_fan_low: trip-fan-low {
					temperature = <70000>;
					hysteresis = <5000>;
					type = "active";
				};
				little_core1_fan_high: trip-fan-high {
					temperature = <85000>;
					hysteresis = <5000>;
					type = "active";
				};
			};

			cooling-maps {
				map0 {
					trip = <&little_core1_passive>;
					cooling-device = <&cpu0 THERMAL_NO_LIMIT THERMAL_NO_LIMIT>,
							 <&cpu4 THERMAL_NO_LIMIT THERMAL_NO_LIMIT>,
							 <&cpu7 THERMAL_NO_LIMIT THERMAL_NO_LIMIT>;
				};
				map1 {
					trip = <&little_core1_fan_low>;
					cooling-device = <&fan 1 1>;
				};
				map2 {
					trip = <&little_core1_fan_high>;
					cooling-device = <&fan 2 2>;
				};
			};
		};

		dsu2-thermal {
			polling-delay = <1000>;
			polling-delay-passive = <250>;
			thermal-sensors = <&lvts_mcu MT6897_MCU_DSU1>;

			trips {
				dsu2_passive: trip-passive {
					temperature = <95000>;
					hysteresis = <2000>;
					type = "passive";
				};
				dsu2_fan_low: trip-fan-low {
					temperature = <70000>;
					hysteresis = <5000>;
					type = "active";
				};
				dsu2_fan_high: trip-fan-high {
					temperature = <85000>;
					hysteresis = <5000>;
					type = "active";
				};
			};

			cooling-maps {
				map0 {
					trip = <&dsu2_passive>;
					cooling-device = <&cpu0 THERMAL_NO_LIMIT THERMAL_NO_LIMIT>,
							 <&cpu4 THERMAL_NO_LIMIT THERMAL_NO_LIMIT>,
							 <&cpu7 THERMAL_NO_LIMIT THERMAL_NO_LIMIT>;
				};
				map1 {
					trip = <&dsu2_fan_low>;
					cooling-device = <&fan 1 1>;
				};
				map2 {
					trip = <&dsu2_fan_high>;
					cooling-device = <&fan 2 2>;
				};
			};
		};

		big7-1-thermal {
			polling-delay = <1000>;
			polling-delay-passive = <250>;
			thermal-sensors = <&lvts_mcu MT6897_MCU_BIG_CPU7_0>;

			trips {
				big_core7_1_passive: trip-passive {
					temperature = <95000>;
					hysteresis = <2000>;
					type = "passive";
				};
				big_core7_1_fan_low: trip-fan-low {
					temperature = <70000>;
					hysteresis = <5000>;
					type = "active";
				};
				big_core7_1_fan_high: trip-fan-high {
					temperature = <85000>;
					hysteresis = <5000>;
					type = "active";
				};
			};

			cooling-maps {
				map0 {
					trip = <&big_core7_1_passive>;
					cooling-device = <&cpu0 THERMAL_NO_LIMIT THERMAL_NO_LIMIT>,
							 <&cpu4 THERMAL_NO_LIMIT THERMAL_NO_LIMIT>,
							 <&cpu7 THERMAL_NO_LIMIT THERMAL_NO_LIMIT>;
				};
				map1 {
					trip = <&big_core7_1_fan_low>;
					cooling-device = <&fan 1 1>;
				};
				map2 {
					trip = <&big_core7_1_fan_high>;
					cooling-device = <&fan 2 2>;
				};
			};
		};

		big7-2-thermal {
			polling-delay = <1000>;
			polling-delay-passive = <250>;
			thermal-sensors = <&lvts_mcu MT6897_MCU_BIG_CPU7_1>;

			trips {
				big_core7_2_passive: trip-passive {
					temperature = <95000>;
					hysteresis = <2000>;
					type = "passive";
				};
				big_core7_2_fan_low: trip-fan-low {
					temperature = <70000>;
					hysteresis = <5000>;
					type = "active";
				};
				big_core7_2_fan_high: trip-fan-high {
					temperature = <85000>;
					hysteresis = <5000>;
					type = "active";
				};
			};

			cooling-maps {
				map0 {
					trip = <&big_core7_2_passive>;
					cooling-device = <&cpu0 THERMAL_NO_LIMIT THERMAL_NO_LIMIT>,
							 <&cpu4 THERMAL_NO_LIMIT THERMAL_NO_LIMIT>,
							 <&cpu7 THERMAL_NO_LIMIT THERMAL_NO_LIMIT>;
				};
				map1 {
					trip = <&big_core7_2_fan_low>;
					cooling-device = <&fan 1 1>;
				};
				map2 {
					trip = <&big_core7_2_fan_high>;
					cooling-device = <&fan 2 2>;
				};
			};
		};

		dsu3-thermal {
			polling-delay = <1000>;
			polling-delay-passive = <250>;
			thermal-sensors = <&lvts_mcu MT6897_MCU_DSU2>;

			trips {
				dsu3_passive: trip-passive {
					temperature = <95000>;
					hysteresis = <2000>;
					type = "passive";
				};
				dsu3_fan_low: trip-fan-low {
					temperature = <70000>;
					hysteresis = <5000>;
					type = "active";
				};
				dsu3_fan_high: trip-fan-high {
					temperature = <85000>;
					hysteresis = <5000>;
					type = "active";
				};
			};

			cooling-maps {
				map0 {
					trip = <&dsu3_passive>;
					cooling-device = <&cpu0 THERMAL_NO_LIMIT THERMAL_NO_LIMIT>,
							 <&cpu4 THERMAL_NO_LIMIT THERMAL_NO_LIMIT>,
							 <&cpu7 THERMAL_NO_LIMIT THERMAL_NO_LIMIT>;
				};
				map1 {
					trip = <&dsu3_fan_low>;
					cooling-device = <&fan 1 1>;
				};
				map2 {
					trip = <&dsu3_fan_high>;
					cooling-device = <&fan 2 2>;
				};
			};
		};

		dsu4-thermal {
			polling-delay = <1000>;
			polling-delay-passive = <250>;
			thermal-sensors = <&lvts_mcu MT6897_MCU_DSU3>;

			trips {
				dsu4_passive: trip-passive {
					temperature = <95000>;
					hysteresis = <2000>;
					type = "passive";
				};
				dsu4_fan_low: trip-fan-low {
					temperature = <70000>;
					hysteresis = <5000>;
					type = "active";
				};
				dsu4_fan_high: trip-fan-high {
					temperature = <85000>;
					hysteresis = <5000>;
					type = "active";
				};
			};

			cooling-maps {
				map0 {
					trip = <&dsu4_passive>;
					cooling-device = <&cpu0 THERMAL_NO_LIMIT THERMAL_NO_LIMIT>,
							 <&cpu4 THERMAL_NO_LIMIT THERMAL_NO_LIMIT>,
							 <&cpu7 THERMAL_NO_LIMIT THERMAL_NO_LIMIT>;
				};
				map1 {
					trip = <&dsu4_fan_low>;
					cooling-device = <&fan 1 1>;
				};
				map2 {
					trip = <&dsu4_fan_high>;
					cooling-device = <&fan 2 2>;
				};
			};
		};

		/*
		 * Interim GPU protection: the GPU's own sensors sit inside its
		 * power domain and are not described yet, so the always-on SoC
		 * sensors drive the fan and throttle the GPU. They lag the GPU.
		 */
		soc-top1-thermal {
			polling-delay = <1000>;
			polling-delay-passive = <250>;
			thermal-sensors = <&lvts_ap MT6897_AP_SOC_TOP0>;

			trips {
				soc_top1_fan_low: trip-fan-low {
					temperature = <70000>;
					hysteresis = <5000>;
					type = "active";
				};
				soc_top1_fan_high: trip-fan-high {
					temperature = <85000>;
					hysteresis = <5000>;
					type = "active";
				};
				soc_top1_passive: trip-passive {
					temperature = <95000>;
					hysteresis = <2000>;
					type = "passive";
				};
			};

			cooling-maps {
				map0 {
					trip = <&soc_top1_passive>;
					cooling-device = <&gpu THERMAL_NO_LIMIT THERMAL_NO_LIMIT>;
				};
				map1 {
					trip = <&soc_top1_fan_low>;
					cooling-device = <&fan 1 1>;
				};
				map2 {
					trip = <&soc_top1_fan_high>;
					cooling-device = <&fan 2 2>;
				};
			};
		};

		/*
		 * Interim GPU protection: the GPU's own sensors sit inside its
		 * power domain and are not described yet, so the always-on SoC
		 * sensors drive the fan and throttle the GPU. They lag the GPU.
		 */
		soc-bot1-thermal {
			polling-delay = <1000>;
			polling-delay-passive = <250>;
			thermal-sensors = <&lvts_ap MT6897_AP_SOC_BOT0>;

			trips {
				soc_bot1_fan_low: trip-fan-low {
					temperature = <70000>;
					hysteresis = <5000>;
					type = "active";
				};
				soc_bot1_fan_high: trip-fan-high {
					temperature = <85000>;
					hysteresis = <5000>;
					type = "active";
				};
				soc_bot1_passive: trip-passive {
					temperature = <95000>;
					hysteresis = <2000>;
					type = "passive";
				};
			};

			cooling-maps {
				map0 {
					trip = <&soc_bot1_passive>;
					cooling-device = <&gpu THERMAL_NO_LIMIT THERMAL_NO_LIMIT>;
				};
				map1 {
					trip = <&soc_bot1_fan_low>;
					cooling-device = <&fan 1 1>;
				};
				map2 {
					trip = <&soc_bot1_fan_high>;
					cooling-device = <&fan 2 2>;
				};
			};
		};

		/*
		 * GPU sensor 0 (vendor TS9_0, zone gpu1). Only reads while
		 * the GPU is powered; while it is off the zone has no value and
		 * its trips do not change state. The SoC zones above keep their
		 * fan and GPU maps until these are proven on hardware.
		 */
		gpu0-thermal {
			polling-delay = <1000>;
			polling-delay-passive = <250>;
			thermal-sensors = <&lvts_gpu MT6897_GPU0>;

			trips {
				gpu0_fan_low: trip-fan-low {
					temperature = <70000>;
					hysteresis = <5000>;
					type = "active";
				};
				gpu0_fan_high: trip-fan-high {
					temperature = <85000>;
					hysteresis = <5000>;
					type = "active";
				};
				gpu0_passive: trip-passive {
					temperature = <95000>;
					hysteresis = <2000>;
					type = "passive";
				};
			};

			cooling-maps {
				map0 {
					trip = <&gpu0_passive>;
					cooling-device = <&gpu THERMAL_NO_LIMIT THERMAL_NO_LIMIT>;
				};
				map1 {
					trip = <&gpu0_fan_low>;
					cooling-device = <&fan 1 1>;
				};
				map2 {
					trip = <&gpu0_fan_high>;
					cooling-device = <&fan 2 2>;
				};
			};
		};

		/*
		 * GPU sensor 1 (vendor TS9_1, zone gpu2). Only reads while
		 * the GPU is powered; while it is off the zone has no value and
		 * its trips do not change state. The SoC zones above keep their
		 * fan and GPU maps until these are proven on hardware.
		 */
		gpu1-thermal {
			polling-delay = <1000>;
			polling-delay-passive = <250>;
			thermal-sensors = <&lvts_gpu MT6897_GPU1>;

			trips {
				gpu1_fan_low: trip-fan-low {
					temperature = <70000>;
					hysteresis = <5000>;
					type = "active";
				};
				gpu1_fan_high: trip-fan-high {
					temperature = <85000>;
					hysteresis = <5000>;
					type = "active";
				};
				gpu1_passive: trip-passive {
					temperature = <95000>;
					hysteresis = <2000>;
					type = "passive";
				};
			};

			cooling-maps {
				map0 {
					trip = <&gpu1_passive>;
					cooling-device = <&gpu THERMAL_NO_LIMIT THERMAL_NO_LIMIT>;
				};
				map1 {
					trip = <&gpu1_fan_low>;
					cooling-device = <&fan 1 1>;
				};
				map2 {
					trip = <&gpu1_fan_high>;
					cooling-device = <&fan 2 2>;
				};
			};
		};
	};
};

/*
 * SPM power domains (full MT6897 table). Registration reads each domain's
 * state and writes nothing: domains the bootloader left on are registered
 * always-on, the rest stay off until a consumer asks. Multimedia sub-block
 * clocks and the camera/ISP supplies are left out because their providers do
 * not exist here yet and would defer the whole controller.
 */
&soc {
	ifr_bus: syscon@1002c000 {
		compatible = "mediatek,mt6897-ifr_bus", "syscon";
		reg = <0x0 0x1002c000 0x0 0x1000>;
	};

	vlpcfg_bus: syscon@1c00c000 {
		compatible = "mediatek,mt6897-vlpcfg_bus", "syscon";
		reg = <0x0 0x1c00c000 0x0 0x1000>;
	};
};

&scpsys {
	infracfg = <&ifr_bus>;
	vlpcfg = <&vlpcfg_bus>;
	hw-voter-regmap = <&hwv>;
	clocks = <&topckgen CLK_TOP_AUD_INTBUS_SEL>,
		 <&topckgen CLK_TOP_ADSP_SEL>,
		 <&topckgen CLK_TOP_IMG1_SEL>,
		 <&topckgen CLK_TOP_IPE_SEL>,
		 <&topckgen CLK_TOP_VDEC_SEL>,
		 <&topckgen CLK_TOP_VENC_SEL>,
		 <&topckgen CLK_TOP_CAM_SEL>,
		 <&topckgen CLK_TOP_DPE_SEL>,
		 <&vlp_cksys CLK_VLP_CK_CCUSYS_SEL>,
		 <&topckgen CLK_TOP_CCU_AHB_SEL>,
		 <&topckgen CLK_TOP_MDP0_SEL>,
		 <&topckgen CLK_TOP_MDP1_SEL>,
		 <&topckgen CLK_TOP_DISP0_SEL>,
		 <&topckgen CLK_TOP_DISP1_SEL>,
		 <&topckgen CLK_TOP_OVL0_SEL>,
		 <&topckgen CLK_TOP_OVL1_SEL>,
		 <&topckgen CLK_TOP_MMINFRA_SEL>,
		 <&topckgen CLK_TOP_MMUP_SEL>;
	clock-names = "audio", "adsp_ao", "isp", "ipe", "vde", "ven",
		      "cam", "dpe", "ccu", "ccu_ahb", "mdp", "mdp1",
		      "disp", "disp1", "ovl", "ovl1", "mm_infra", "mmup";
	status = "okay";
};

/*
 * Cooling fan. PWM channel 0 on GPIO115 (already muxed by the bootloader),
 * supply switch on GPIO4. The vendor driver programs the high time as
 * (256 - level), i.e. the fan runs faster the longer the line is low, so the
 * levels below are inverted: 255 = stopped, 96 = vendor "cool" (160),
 * 1 = vendor "max" (255). Thresholds follow the vendor policy: 70 and 85 degC.
 */
/ {
	fan_vcc: regulator-fan-vcc {
		compatible = "regulator-fixed";
		regulator-name = "fan-vcc";
		gpio = <&pio 4 GPIO_ACTIVE_HIGH>;
		enable-active-high;
	};

	fan: pwm-fan {
		compatible = "pwm-fan";
		pwms = <&pwm 0 40000>;
		fan-supply = <&fan_vcc>;
		cooling-levels = <255 96 1>;
		#cooling-cells = <2>;
		pinctrl-names = "default";
		pinctrl-0 = <&fan_pins_default>;
	};
};

&pio {
	fan_pins_default: fan-default-pins {
		pins-pwm {
			pinmux = <0x7305>;
		};
	};
};

&pwm {
	clocks = <&pericfg CLK_PERAOP_PWM_HCLK>,
		 <&pericfg CLK_PERAOP_PWM_BCLK>,
		 <&pericfg CLK_PERAOP_PWM_FBCLK1>,
		 <&pericfg CLK_PERAOP_PWM_FBCLK2>,
		 <&pericfg CLK_PERAOP_PWM_FBCLK3>,
		 <&pericfg CLK_PERAOP_PWM_FBCLK4>;
	clock-names = "top", "main", "pwm1", "pwm2", "pwm3", "pwm4";
	/* The source selectors reset to 32 kHz; the fan needs 25 kHz PWM. */
	assigned-clocks = <&pericfg CLK_PERAOP_PWM_BSEL>,
			  <&pericfg CLK_PERAOP_PWM_FB1_SEL>;
	assigned-clock-parents = <&clk26m>, <&clk26m>;
	status = "okay";
};

/*
 * Backlight PWM. The bootloader leaves it running on GPIO131; the boot
 * framebuffer holds its clock so that it stays lit whoever else comes and goes.
 */
&pio {
	disp_pwm_pins_default: disp-pwm-default-pins {
		pins-pwm {
			pinmux = <0x8301>;
		};
	};
};

/ {
	/*
	 * No enable-gpios on purpose: the LED driver's enable is believed to
	 * share GPIO64 with the panel supply, which must not be switched yet.
	 */
	backlight: backlight {
		compatible = "pwm-backlight";
		pwms = <&disp_pwm0 0 39385>;
		brightness-levels = <0 255>;
		num-interpolated-steps = <255>;
		default-brightness-level = <51>;
	};
};

&disp_pwm0 {
	clocks = <&pericfg CLK_PERAOP_DISP_PWM0>,
		 <&topckgen CLK_TOP_DISP_PWM_SEL>;
	clock-names = "main", "mm";
	pinctrl-names = "default";
	pinctrl-0 = <&disp_pwm_pins_default>;
	status = "okay";
};

/*
 * Display: mediatek-drm on DSI0 (OVL0_2L in OVLSYS0 -> DISPSYS0 PQ bypass ->
 * DSI0 -> Truly FT8201P). Until the first modeset the bootloader's pipeline
 * keeps running and the console stays on simpledrm; mediatek-drm removes the
 * boot framebuffer when it binds. The panel supplies (GPIO63/GPIO64, PMIC
 * VFP) are deliberately not described: they must not be switched yet.
 */
&mipi_tx0 {
	status = "okay";
};

&disp_mutex0 {
	status = "okay";
};

&ovlsys0_mutex {
	status = "okay";
};

&ovl0_2l {
	status = "okay";
};

&dsi0 {
	status = "okay";

	panel@0 {
		compatible = "truly,ft8201p";
		reg = <0>;
		reset-gpios = <&pio 41 GPIO_ACTIVE_LOW>;
		backlight = <&backlight>;

		port {
			panel_in: endpoint {
				remote-endpoint = <&dsi0_out>;
			};
		};
	};

	port {
		dsi0_out: endpoint {
			remote-endpoint = <&panel_in>;
		};
	};
};

/*
 * Touchscreen: the touch half of the FT8201P panel controller. It only answers
 * while the panel is powered and initialised. Supply (MT6368 VTP) is always on.
 */
&pio {
	touch_pins_default: touch-default-pins {
		pins-i2c {
			pinmux = <0xa301>, <0xa401>;
		};

		pins-irq {
			pinmux = <0x0900>;
			input-enable;
			bias-pull-up;
		};
	};
};

&i2c13 {
	clock-frequency = <400000>;
	pinctrl-names = "default";
	pinctrl-0 = <&touch_pins_default>;
	status = "okay";

	touchscreen@38 {
		compatible = "focaltech,ft8201";
		reg = <0x38>;
		interrupts-extended = <&pio 9 IRQ_TYPE_EDGE_FALLING>;
		reset-gpios = <&pio 60 GPIO_ACTIVE_LOW>;
		touchscreen-size-x = <1280>;
		touchscreen-size-y = <960>;
	};
};

/*
 * GPU: Mali-G615 MC6 behind the GPUEB.
 *
 * The bootloader starts the GPUEB, which owns the GPU bucks (MT6368 VBUCK2,
 * MT6363 VSRAM_MDFE), MFG MTCMOS, MFGPLL/MFGSCPLL and DVFS. The AP only talks
 * to it over the mailbox; nothing here describes a regulator or a real clock.
 *
 * Stage A/B: gpueb_mbox and gpufreq probe passively; the IPI steps are run by
 * hand from /sys/kernel/debug/mt6897_gpu/.
 * Stage C: set the gpu node's status to "okay" (the one marked line below).
 */
&soc {
	gpueb_mbox: mailbox@13c2fd80 {
		compatible = "mediatek,mt6897-gpueb-mbox";
		reg = <0x0 0x13c2fd80 0x0 0x280>,
		      <0x0 0x13c62000 0x0 0x7c>;
		reg-names = "data", "ctl";
		interrupts = <GIC_SPI 588 IRQ_TYPE_LEVEL_HIGH 0>;
		#mbox-cells = <1>;
	};

	gpufreq: power-controller@13c2fd1c {
		compatible = "mediatek,mt6897-gpufreq";
		reg = <0x0 0x13c2fd1c 0x0 0x64>,
		      <0x0 0x13f91000 0x0 0x1000>,
		      <0x0 0x1c001fc0 0x0 0x8>,
		      <0x0 0x13c620a8 0x0 0x4>,
		      <0x0 0x13000000 0x0 0x1000>,
		      <0x0 0x13fa000c 0x0 0x4>,
		      <0x0 0x13fa0c0c 0x0 0x4>,
		      <0x0 0x100001f0 0x0 0x4>;
		/* the last three are read only, for frequency readback */
		reg-names = "gpr", "rpc", "spm-status", "pdca-sta", "gpu",
			    "mfgpll-con1", "mfgscpll-con1", "topck-mfg-sel";
		memory-region = <&gpueb_gpufreq_mem>;
		mboxes = <&gpueb_mbox 0>, <&gpueb_mbox 1>, <&gpueb_mbox 2>,
			 <&gpueb_mbox 3>, <&gpueb_mbox 4>, <&gpueb_mbox 5>,
			 <&gpueb_mbox 6>, <&gpueb_mbox 7>, <&gpueb_mbox 8>,
			 <&gpueb_mbox 9>, <&gpueb_mbox 10>;
		mbox-names = "fast-dvfs-event", "gpufreq", "sleep", "timer",
			     "fhctl", "ccf", "gpumpu", "fast-dvfs",
			     "ipir-c-met", "ipis-c-met", "brisket";
		#clock-cells = <0>;
		#power-domain-cells = <0>;
	};

	gpu: gpu@13000000 {
		#cooling-cells = <2>;	/* panthor devfreq cooling */
		compatible = "mediatek,mt6897-mali", "arm,mali-valhall-csf";
		reg = <0x0 0x13000000 0x0 0x480000>;
		interrupts = <GIC_SPI 586 IRQ_TYPE_LEVEL_HIGH 0>,
			     <GIC_SPI 585 IRQ_TYPE_LEVEL_HIGH 0>,
			     <GIC_SPI 584 IRQ_TYPE_LEVEL_HIGH 0>;
		interrupt-names = "job", "mmu", "gpu";
		/* read-only view of the EB's frequency; gates nothing */
		clocks = <&gpufreq>;
		clock-names = "core";
		power-domains = <&gpufreq>;
		status = "okay";
	};
};
